# SF32LB52x register map
File version: 1.0
CPU: CM33 r0p1, little endian, MPU, FPU, 3 interrupt priority bits
Registers are 32-bit, read-write, reset 0x0 unless marked. A register's access mark holds for its fields unless they carry their own. Offsets are from the block's base; [hi:lo] are bit positions.

## SDMMC1
Base 0x50045000
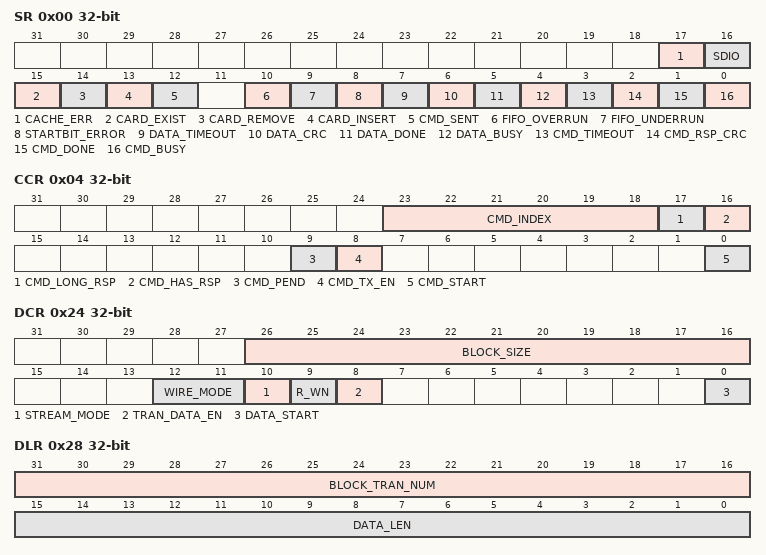
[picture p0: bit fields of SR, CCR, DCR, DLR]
0x00 SR — command and data status register
  [17] CACHE_ERR — Detect cache error Read 1: cache error occur Read 0: no cache error Write 1: clear the bit Write 0: no any influence to the bit
  [16] SDIO — Detect SDIO Card Interrupt Read 1: detect sdio card generating interrupt Read 0: no interrupt Write 1: clear the bit Write 0: no any influence to the bit
  [15] CARD_EXIST — Card exist status Read 1: card exist Read 0: no card exist This bit will be valid after enable detect card.
  [14] CARD_REMOVE — Detect card removed Read 1: detect card removed. When detect card inserted bit is set, the bit will also be back to 0 Read 0: no meaning Write 1: clear the bit Write 0: no any influence to the bit
  [13] CARD_INSERT — Detect card inserted Read 1: detect card inserted. When detect card removed bit is set, the bit will also be back to 0 Read 0: no meaning Write 1: clear the bit Write 0: no any influence to the bit
  [12] CMD_SENT — Command sent (perhaps no response back yet) Read 1: command sent. When command start bit is set, the bit will also be back to 0 Read 0: command transferring or others Write 1: clear the bit Write 0: no any influence to the bit
  [10] FIFO_OVERRUN — FIFO overrun Read 1: FIFO overrun error Read 0: no FIFO overrun error Write 1: clear the bit Write 0: no any influence to the bit
  [9] FIFO_UNDERRUN — FIFO underrun Read 1: FIFO underrun error Read 0: no FIFO underrun error Write 1: clear the bit Write 0: no any influence to the bit
  [8] STARTBIT_ERROR — Wide bus start bits error Didn't detect all start bits in data bus Read 1: start bits error Read 0: no start bits error Write 1: clear the bit Write 0: no any influence to the bit
  [7] DATA_TIMEOUT — Data timeout Read 1: timeout Read 0: no timeout Write 1: clear the bit Write 0: no any influence to the bit
  [6] DATA_CRC — Data CRC error Read 1: data CRC error Read 0: data CRC right Write 1: clear the bit Write 0: no any influence to the bit
  [5] DATA_DONE — Data transfer done Read 1: transfer data done, and start a new transfer will take the bit into 0 Read 0: data transferring or idle Write 1: clear the bit Write 0: no any influence to the bit
  [4] DATA_BUSY — Transfer Data busy 1: busy, and when busy, start transfer data bit is no usage and you should not modify the relative register. If want to do this, first disable transfer data enable bit, then the busy bit will be back to 0, and this transfer will also be cancelled. 0: data idle
  [3] CMD_TIMEOUT — Command timeout (response timeout) Read 1: timeout Read 0: no timeout Write 1: clear the bit Write 0: no any influence to the bit
  [2] CMD_RSP_CRC — Command response CRC error status Read 1: response CRC error Read 0: response CRC right Write 1: clear the bit Write 0: no any influence to the bit
  [1] CMD_DONE — Command done Read 1: transfer command done, and start a new transfer will take the bit into 0 Read 0: command transferring or idle Write 1: clear the bit Write 0: no any influence to the bit
  [0] CMD_BUSY — Command busy 1: busy, and when busy, start TX command bit is no usage and should not modify the relative register 0: command idle
0x04 CCR — command control register
  [23:18] CMD_INDEX — Command index
  [17] CMD_LONG_RSP — 1: Response will be 136-bit, long response 0: Response will be 48-bit, normal response
  [16] CMD_HAS_RSP — 1: Response expected after command 0: No response expected after command
  [9] CMD_PEND — Command pending enable When prepare to send stop command, this bit should be set. Controller will calculate a proper time point to send out the command to guarantee all the data have been transferred. And this is mainly used in stream mode. Recommend using set_block_count (SD/MMC basis command) to control transferring data for block mode. If send stop command for canceling this transfer (such as CRC error in multi-block), no need to set the bit.
  [8] CMD_TX_EN — TX command enable 1: enable TX command 0: disable TX command
  [0] CMD_START — Command start write 1 to start command TX, and when begin to TX command, the bit will return into 0.
0x08 CAR — command argument register
  [31:0] CMD_ARG — Command argument
0x0C RIR — response command index register
  [5:0] RSP_INDEX — Response command index
0x10 RAR1 — response command argument1 register
  [31:0] RSP_ARG1 — Response command content If long response, it is rsp_arg[39:8]
0x14 RAR2 — response command argument2 register
  [31:0] RSP_ARG2 — Long response, it is rsp_arg[71:40]
0x18 RAR3 — response command argument3 register
  [31:0] RSP_ARG3 — Long response, it is rsp_arg[103:72]
0x1C RAR4 — response command argument4 register
  [23:0] RSP_ARG4 — Long response, it is rsp_arg[127:104]
0x20 TOR — timeout count register
  [31:0] TIMEOUT_CNT — Used to determine how much time waiting response or data bus busy is timeout, and decreased under card clock. Set to 400000 for 1s timeout if interface clock is 400KHz.
0x24 DCR — data control register
  [26:16] BLOCK_SIZE — Data block size is block_size+1 (max 2048 bytes) 0: 1 byte 0x1ff: 512 bytes
  [12:11] WIRE_MODE — Wide data bus mode 00: 1 wire bus 01: 4 wires wide bus 1X: reserved
  [10] STREAM_MODE — Data transfer mode 0: block 1: stream
  [9] R_WN — Write or read 0: write data into card 1: read data from card
  [8] TRAN_DATA_EN — Transfer data enable 0: disable transfer data. After disable data transfer, stop command should be sent to card 1: enable data transfer
  [0] DATA_START — Start transfer data set 1 to let the controller begin to transfer data (in fact, go into wait write or wait read state). After begin to transfer, this bit will be back to 0.
0x28 DLR — data length register
  [31:16] BLOCK_TRAN_NUM — The number of blocks which have been transferred successfully 1 = 1 block transferred It is cleared when start transfer data bit is set.
  [15:0] DATA_LEN — Data length value. The number of data bytes is data_len+1. The number of data bytes should be a multiple of data block size. 0 is 1 byte. 0x1ff is 512 bytes. Max is 63.5KB.
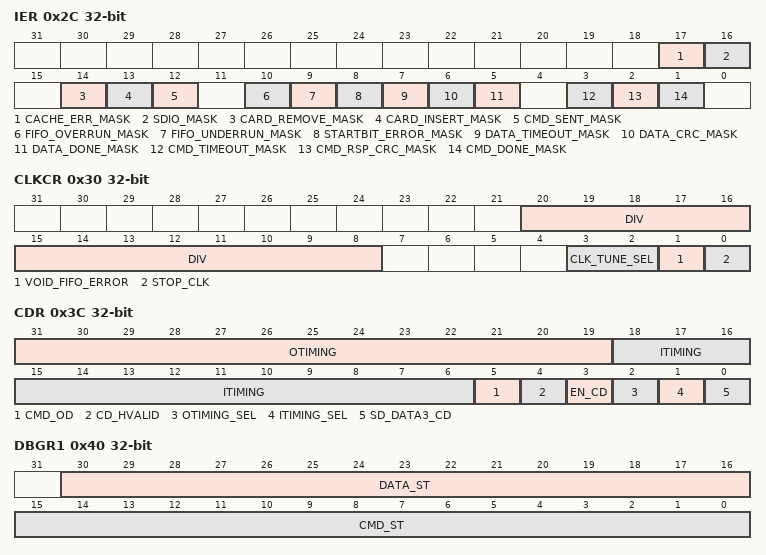
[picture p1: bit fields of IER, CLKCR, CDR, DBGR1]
0x2C IER — command and data interrupt mask register
  [17] CACHE_ERR_MASK — cache error mask for interrupt
  [16] SDIO_MASK — Detect SDIO interrupt(data[1]) mask for interrupt
  [14] CARD_REMOVE_MASK — Detect card remove mask for interrupt
  [13] CARD_INSERT_MASK — Detect card insert mask for interrupt
  [12] CMD_SENT_MASK — Command sent mask for interrupt
  [10] FIFO_OVERRUN_MASK — FIFO overrun bit mask for interrupt
  [9] FIFO_UNDERRUN_MASK — FIFO underrun bit mask for interrupt
  [8] STARTBIT_ERROR_MASK — Wide bus start bits error bit mask for interrupt
  [7] DATA_TIMEOUT_MASK — Data timeout bit mask for interrupt
  [6] DATA_CRC_MASK — Data CRC error bit mask for interrupt
  [5] DATA_DONE_MASK — Data transfer done bit mask for interrupt
  [3] CMD_TIMEOUT_MASK — Command timeout bit mask for interrupt
  [2] CMD_RSP_CRC_MASK — Command CRC error bit mask for interrupt
  [1] CMD_DONE_MASK — Command done bit mask for interrupt
0x30 CLKCR — clock control register
  [20:8] DIV — Divide card clock counter. 0 is illegal. sd_clock = hclk/(div + 1) If hclk is 240M and div is 599, 400KHz SD clock will be generated.
  [3:2] CLK_TUNE_SEL — select clock delay for rx sample 0: no delay 1: delay level 1 (~1.5ns typical) 2: delay level 2 (~3ns typical) 3: delay level 3 (~5ns typical)
  [1] VOID_FIFO_ERROR — Void FIFO error 0: close the function 1: open the function If open it, when FIFO will be overrun or underrun soon, the SD_CLK and the clock enable of this module will be closed, and wait to host to read or write FIFO. Note: this function needs to be supported by card.
  [0] STOP_CLK — Disable SD card clock 1: stop SD card clock 0: SD card clock generated
0x3C CDR — card interface control and card detect register
  [31:19] OTIMING — define output timing
  [18:6] ITIMING — define input timing
  [5] CMD_OD — Open Drain mode for cmd line (for eMMC identification mode) 0: cmd line is push-pull 1: cmd line is open-drain
  [4] CD_HVALID — Card detect high level valid 0: detect low level means card exist 1: detect high level means card exist (default)
  [3] EN_CD — Enable card detect Only when the bit is valid, controller does card detect. If use sd_data[3] to do card detect, the bit should be cleared when transfer valid data.
  [2] OTIMING_SEL — select output timing (according to otiming config)
  [1] ITIMING_SEL — select input sample timing (according to itiming config)
  [0] SD_DATA3_CD — Use sd_data[3] to do card detect 0: use special pin to do card detect / write protect. (Currently not supported) 1: use sd_data[3] to do card detect (default)
0x40 DBGR1 — card debug port1 register
  [30:16] DATA_ST — data state for debug only
  [15:0] CMD_ST — command state for debug only
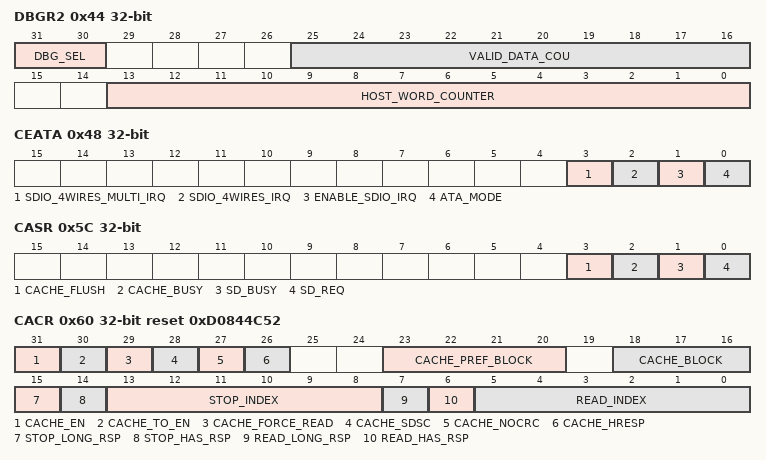
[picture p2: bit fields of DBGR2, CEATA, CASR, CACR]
0x44 DBGR2 — card debug port2 register
  [31:30] DBG_SEL — for debug only
  [25:16] VALID_DATA_COU — for debug only
  [13:0] HOST_WORD_COUNTER — for debug only
0x48 CEATA — CE-ATA/SDIO mode register
  [3] SDIO_4WIRES_MULTI_IRQ — Select the sdio host 4 wires interrupt on multi-block support 0: host not support 4 wires interrupt on multi-block data transfers 1: host support 4 wires interrupt on multi-block data transfers
  [2] SDIO_4WIRES_IRQ — Select the sdio host 4 wires interrupt support 0: host not support 4 wires interrupt on single-block data transfers 1: host support 4 wires interrupt on single-block data transfers
  [1] ENABLE_SDIO_IRQ — Select the sdio card mode, default is sd card 0: sd card mode , no sdio card interrupt 1: sdio card mode , enable sdio card interrupt
  [0] ATA_MODE — Select the card type, default is sd card 0: sd card mode 1: CE-ATA device mode
0x54 DSR — data status register
  [7:0] SD_DATA_I_LL — The status of each sd data pad status
0x58 CDCR reset 0x1 — clock duty cycle register
  [0] CLK_CONFIG — 1: the sd clock is 50% duty cycle 0: the high level of the sd clock is 1 hclk cycle
0x5C CASR — cache status register
  [3] CACHE_FLUSH — Set 1 to flush cache. Should set when cache not busy.
  [2] CACHE_BUSY — Indicates cache is working
  [1] SD_BUSY — Read 1 indicates sd is ready for normal access. Ahb access will be hold during sd_busy asserted. After sd normal access done, write 1 to clear, and ahb access will continue
  [0] SD_REQ — Set 1 to request sd normal access. sd_req will be cleared automatically after sd_busy asserted
0x60 CACR reset 0xD0844C52 — cache control register
  [31] CACHE_EN — enable cache 1: ahb read will return cached data 0: ahb read always return dummy data with no error response
  [30] CACHE_TO_EN — enable ahb read timeout recover
  [29] CACHE_FORCE_READ — force cache read done 1: start new fetch for miss access only after cache read done 0: start new fetch for miss access even when cache is still filling (read will be breaked by cmd12)
  [28] CACHE_SDSC — select card version 1: card size (=2GB, address of cmd18 is in byte 0: card size >2GB, address of cmd18 is in block
  [27] CACHE_NOCRC — 1: return ahb data without crc check 0: return ahb data after block crc pass
  [26] CACHE_HRESP — 1: generate ahb error response when error occur 0: no ahb error response generated. Could check cache_err interrupt
  [23:20] CACHE_PREF_BLOCK — cache prefetch depth is cache_pref_block blocks. Should be no less than cache_block
  [18:16] CACHE_BLOCK — cache depth is cache_block blocks
  [15] STOP_LONG_RSP — Stop response is 136-bit, long response
  [14] STOP_HAS_RSP — Stop command have a response
  [13:8] STOP_INDEX — Command index for stop. CMD12 by default
  [7] READ_LONG_RSP — Read response is 136-bit, long response
  [6] READ_HAS_RSP — Read command have a response
  [5:0] READ_INDEX — Command index for cache read. CMD18 by default
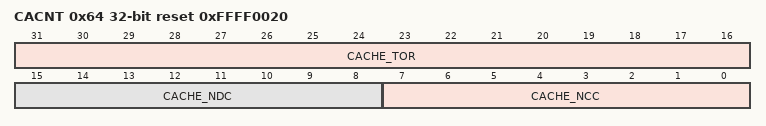
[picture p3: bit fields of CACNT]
0x64 CACNT reset 0xFFFF0020 — cache counter register
  [31:16] CACHE_TOR — timeout count register for ahb read
  [15:8] CACHE_NDC — data-cmd interval counter in hclk cycles
  [7:0] CACHE_NCC — cmd-cmd interval counter in hclk cycles
0x68 CAOFF — cache offset register
  [31:0] CACHE_OFFSET — offset to map ahb address to sd address for ahb access
0x200 FIFO — FIFO entry
  [31:0] DATA — Entry to access internal FIFO. Access should be word-aligned, ranging from 0x200 to 0x3fc. Inside the range, write to any address will push the data into the FIFO, and read any address will pop a word from the FIFO.
